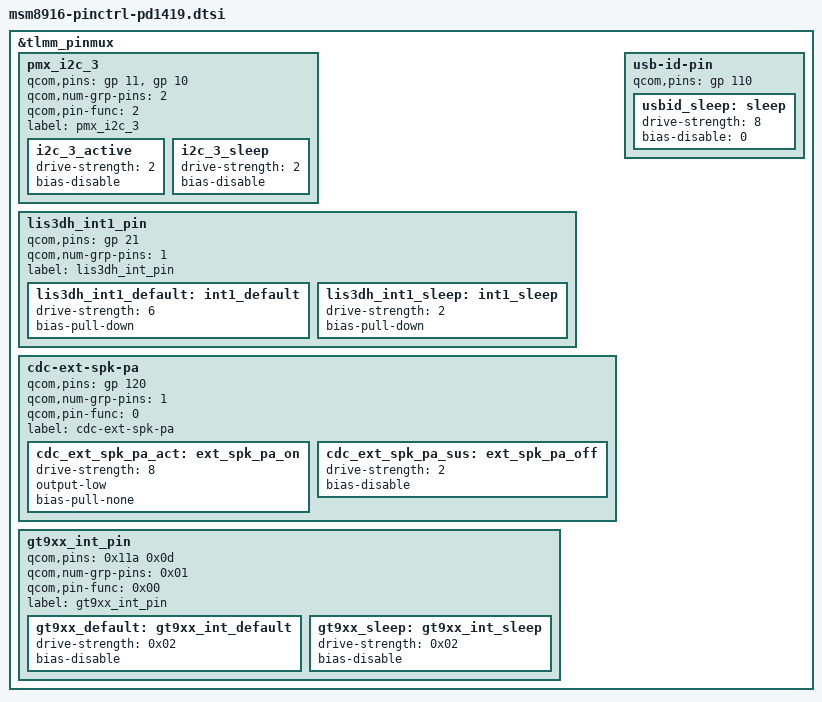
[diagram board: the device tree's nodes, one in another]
/* Copyright (c) 2018, The Linux Foundation. All rights reserved.
*  Copyright (c) 2018, Ketut P. Kumajaya.
*  Copyright (c) 2020, the_shahnawaz_sheikh (sheikhshahnawaz41299).
*
* This program is free software; you can redistribute it and/or modify
* it under the terms of the GNU General Public License version 2 and
* only version 2 as published by the Free Software Foundation.
*
* This program is distributed in the hope that it will be useful,
* but WITHOUT ANY WARRANTY; without even the implied warranty of
* MERCHANTABILITY or FITNESS FOR A PARTICULAR PURPOSE.  See the
* GNU General Public License for more details.
*/
 
&tlmm_pinmux {
	pmx_i2c_3 {
		/* CLK, DATA */
		qcom,pins = <&gp 11>, <&gp 10>;
		qcom,num-grp-pins = <2>;
		qcom,pin-func = <2>;
		label = "pmx_i2c_3";

		i2c_3_active: i2c_3_active {
			drive-strength = <2>; /* 2 MA */
			bias-disable;		  /* No PULL */
		};

		i2c_3_sleep: i2c_3_sleep {
			drive-strength = <2>; /* 2 MA */
			bias-disable;		  /* No PULL */
		};
	};

	lis3dh_int1_pin {
		qcom,pins = <&gp 21>;
		qcom,num-grp-pins = <1>;
		label = "lis3dh_int_pin";
		lis3dh_int1_default: int1_default {
			drive-strength = <6>;
			bias-pull-down;
		};
		lis3dh_int1_sleep: int1_sleep {
			drive-strength = <2>;
			bias-pull-down;
		};
	};

	cdc-ext-spk-pa {
		qcom,pins = <&gp 120>;
		qcom,num-grp-pins = <1>;
		qcom,pin-func = <0>;
		label = "cdc-ext-spk-pa";
		cdc_ext_spk_pa_act: ext_spk_pa_on {
			drive-strength = <8>;
			output-low;
			bias-pull-none;
		};
		cdc_ext_spk_pa_sus: ext_spk_pa_off {
			drive-strength = <2>;
			bias-disable;
		};
	};

	gt9xx_int_pin {
		qcom,pins = <0x11a 0x0d>;
		qcom,num-grp-pins = <0x01>;
		qcom,pin-func = <0x00>;
		label = "gt9xx_int_pin";

		gt9xx_default: gt9xx_int_default {
			drive-strength = <0x02>;
			bias-disable;
		};

		gt9xx_sleep: gt9xx_int_sleep {
			drive-strength = <0x02>;
			bias-disable;
		};
	};

	usb-id-pin {
		qcom,pins = <&gp 110>;

		usbid_sleep: sleep {
			drive-strength = <8>;
			bias-disable = <0>;
		};
	};
};
